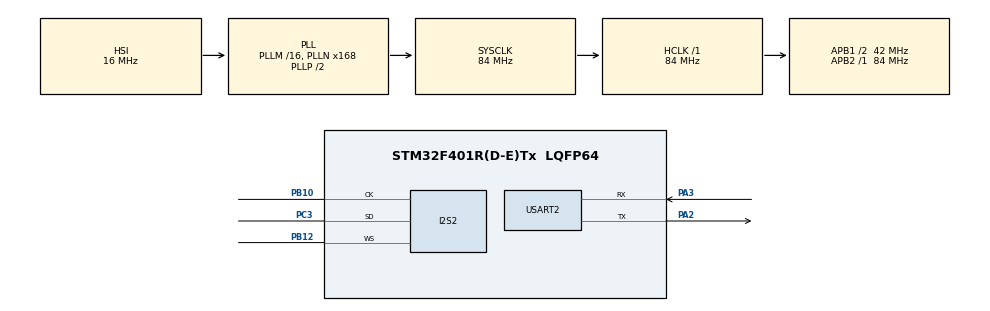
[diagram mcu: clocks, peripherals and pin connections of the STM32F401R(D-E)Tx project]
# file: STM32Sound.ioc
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Dma.Request0=SPI2_TX
Dma.Request1=USART2_TX
Dma.SPI2_TX.0.Direction=DMA_MEMORY_TO_PERIPH
Dma.SPI2_TX.0.FIFOMode=DMA_FIFOMODE_DISABLE
Dma.SPI2_TX.0.Instance=DMA1_Stream4
Dma.SPI2_TX.0.MemDataAlignment=DMA_MDATAALIGN_HALFWORD
Dma.SPI2_TX.0.MemInc=DMA_MINC_ENABLE
Dma.SPI2_TX.0.Mode=DMA_NORMAL
Dma.SPI2_TX.0.PeriphDataAlignment=DMA_PDATAALIGN_HALFWORD
Dma.SPI2_TX.0.PeriphInc=DMA_PINC_DISABLE
Dma.SPI2_TX.0.Priority=DMA_PRIORITY_HIGH
Dma.USART2_TX.1.Direction=DMA_MEMORY_TO_PERIPH
Dma.USART2_TX.1.FIFOMode=DMA_FIFOMODE_DISABLE
Dma.USART2_TX.1.Instance=DMA1_Stream6
Dma.USART2_TX.1.MemDataAlignment=DMA_MDATAALIGN_BYTE
Dma.USART2_TX.1.MemInc=DMA_MINC_ENABLE
Dma.USART2_TX.1.Mode=DMA_NORMAL
Dma.USART2_TX.1.PeriphDataAlignment=DMA_PDATAALIGN_BYTE
Dma.USART2_TX.1.PeriphInc=DMA_PINC_DISABLE
Dma.USART2_TX.1.Priority=DMA_PRIORITY_LOW
I2S2.AudioFreq=I2S_AUDIOFREQ_44K
I2S2.CPOL=I2S_CPOL_HIGH
I2S2.ErrorAudioFreq=0.26 %
I2S2.FullDuplexMode=I2S_FULLDUPLEXMODE_DISABLE
I2S2.Instance=SPI$Index
I2S2.RealAudioFreq=44.117 KHz
I2S2.VirtualMode=I2S_MODE_MASTER
Mcu.Family=STM32F4
Mcu.Name=STM32F401R(D-E)Tx
Mcu.Package=LQFP64
NVIC.DMA1_Stream4_IRQn=true\:0\:0\:false\:false\:true\:false\:true
NVIC.DMA1_Stream6_IRQn=true\:0\:0\:false\:false\:true\:false\:true
NVIC.PriorityGroup=NVIC_PRIORITYGROUP_4
NVIC.USART2_IRQn=true\:0\:0\:false\:false\:true\:true\:true
PA2.GPIO_Speed=GPIO_SPEED_FREQ_HIGH
PA2.Mode=Asynchronous
PA2.Signal=USART2_TX
PA3.GPIO_Speed=GPIO_SPEED_FREQ_HIGH
PA3.Mode=Asynchronous
PA3.Signal=USART2_RX
PB10.Mode=Half_Duplex_Master
PB10.Signal=I2S2_CK
PB12.Mode=Half_Duplex_Master
PB12.Signal=I2S2_WS
PC3.Mode=Half_Duplex_Master
PC3.Signal=I2S2_SD
ProjectManager.HeapSize=0x200
ProjectManager.StackSize=0x400
ProjectManager.TargetToolchain=Makefile
RCC.48MHZClocksFreq_Value=42000000
RCC.AHBFreq_Value=84000000
RCC.APB1CLKDivider=RCC_HCLK_DIV2
RCC.APB1Freq_Value=42000000
RCC.APB1TimFreq_Value=84000000
RCC.APB2Freq_Value=84000000
RCC.APB2TimFreq_Value=84000000
RCC.CortexFreq_Value=84000000
RCC.HCLKFreq_Value=84000000
RCC.HSE_VALUE=25000000
RCC.HSI_VALUE=16000000
RCC.LSE_VALUE=32768
RCC.PLLN=168
RCC.SYSCLKFreq_VALUE=84000000
RCC.SYSCLKSource=RCC_SYSCLKSOURCE_PLLCLK
RCC.VCOOutputFreq_Value=168000000
TIM2.Prescaler=8400
USART2.VirtualMode=VM_ASYNC
VP_TIM2_VS_ClockSourceINT.Mode=Internal
board=custom

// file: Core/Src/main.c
/* USER CODE BEGIN Header */
/**
 ******************************************************************************
 * @file           : main.c
 * @brief          : Main program body
 ******************************************************************************
 * @attention
 *
 * <h2><center>&copy; Copyright (c) 2021 STMicroelectronics.
 * All rights reserved.</center></h2>
 *
 * This software component is licensed by ST under BSD 3-Clause license,
 * the "License"; You may not use this file except in compliance with the
 * License. You may obtain a copy of the License at:
 *                        opensource.org/licenses/BSD-3-Clause
 *
 ******************************************************************************
 */
/* USER CODE END Header */
#include "main.h"
#include "dma.h"
#include "gpio.h"
#include "i2s.h"
#include "tim.h"
#include "usart.h"

/* USER CODE BEGIN Includes */
#include "logger.h"

/* USER CODE END Includes */

void SystemClock_Config(void);

int main(void) {

    /* MCU Configuration--------------------------------------------------------*/

    /* Reset of all peripherals, Initializes the Flash interface and the Systick. */
    HAL_Init();

    /* Configure the system clock */
    SystemClock_Config();

    /* Initialize all configured peripherals */
    MX_GPIO_Init();
    MX_DMA_Init();
    MX_I2S2_Init();
    MX_TIM2_Init();
    MX_USART2_UART_Init();
    /* USER CODE BEGIN 2 */

    writeLog("Initialization completed");

    /* USER CODE END 2 */

    /* Infinite loop */
    while (1) {

        /* USER CODE BEGIN 3 */
        HAL_Delay(999);

        writeLog("Another one bites the dust");
    }
    /* USER CODE END 3 */
}

void SystemClock_Config(void) {
    RCC_OscInitTypeDef RCC_OscInitStruct = {0};
    RCC_ClkInitTypeDef RCC_ClkInitStruct = {0};

    /** Configure the main internal regulator output voltage
     */
    __HAL_RCC_PWR_CLK_ENABLE();
    __HAL_PWR_VOLTAGESCALING_CONFIG(PWR_REGULATOR_VOLTAGE_SCALE2);
    /** Initializes the RCC Oscillators according to the specified parameters
     * in the RCC_OscInitTypeDef structure.
     */
    RCC_OscInitStruct.OscillatorType = RCC_OSCILLATORTYPE_HSI;
    RCC_OscInitStruct.HSIState = RCC_HSI_ON;
    RCC_OscInitStruct.HSICalibrationValue = RCC_HSICALIBRATION_DEFAULT;
    RCC_OscInitStruct.PLL.PLLState = RCC_PLL_ON;
    RCC_OscInitStruct.PLL.PLLSource = RCC_PLLSOURCE_HSI;
    RCC_OscInitStruct.PLL.PLLM = 16;
    RCC_OscInitStruct.PLL.PLLN = 168;
    RCC_OscInitStruct.PLL.PLLP = RCC_PLLP_DIV2;
    RCC_OscInitStruct.PLL.PLLQ = 4;
    if (HAL_RCC_OscConfig(&RCC_OscInitStruct) != HAL_OK) {
        Error_Handler();
    }
    /** Initializes the CPU, AHB and APB buses clocks
     */
    RCC_ClkInitStruct.ClockType = RCC_CLOCKTYPE_HCLK | RCC_CLOCKTYPE_SYSCLK | RCC_CLOCKTYPE_PCLK1 | RCC_CLOCKTYPE_PCLK2;
    RCC_ClkInitStruct.SYSCLKSource = RCC_SYSCLKSOURCE_PLLCLK;
    RCC_ClkInitStruct.AHBCLKDivider = RCC_SYSCLK_DIV1;
    RCC_ClkInitStruct.APB1CLKDivider = RCC_HCLK_DIV2;
    RCC_ClkInitStruct.APB2CLKDivider = RCC_HCLK_DIV1;

    if (HAL_RCC_ClockConfig(&RCC_ClkInitStruct, FLASH_LATENCY_2) != HAL_OK) {
        Error_Handler();
    }
}

void Error_Handler(void) {
    __disable_irq();
    while (1) {
    }
}

/************************ (C) COPYRIGHT STMicroelectronics *****END OF FILE****/
